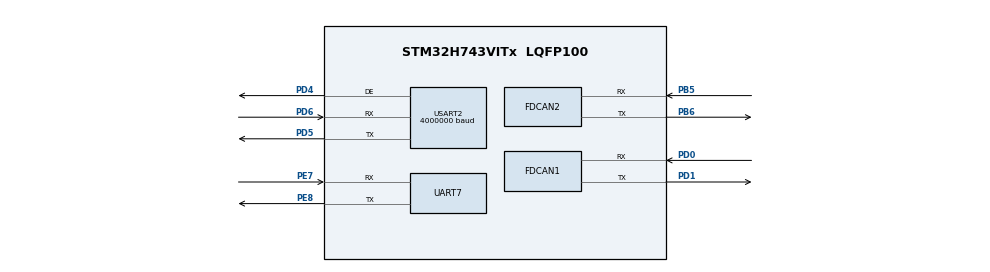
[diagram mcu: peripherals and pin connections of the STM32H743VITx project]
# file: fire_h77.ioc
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Dma.Request0=USART2_RX
Dma.Request1=USART2_TX
Dma.Request2=UART7_RX
Dma.UART7_RX.2.Direction=DMA_PERIPH_TO_MEMORY
Dma.UART7_RX.2.EventEnable=DISABLE
Dma.UART7_RX.2.FIFOMode=DMA_FIFOMODE_DISABLE
Dma.UART7_RX.2.Instance=DMA1_Stream2
Dma.UART7_RX.2.MemDataAlignment=DMA_MDATAALIGN_BYTE
Dma.UART7_RX.2.MemInc=DMA_MINC_ENABLE
Dma.UART7_RX.2.Mode=DMA_NORMAL
Dma.UART7_RX.2.PeriphDataAlignment=DMA_PDATAALIGN_BYTE
Dma.UART7_RX.2.PeriphInc=DMA_PINC_DISABLE
Dma.UART7_RX.2.Polarity=HAL_DMAMUX_REQ_GEN_RISING
Dma.UART7_RX.2.Priority=DMA_PRIORITY_LOW
Dma.UART7_RX.2.RequestNumber=1
Dma.UART7_RX.2.SignalID=NONE
Dma.UART7_RX.2.SyncEnable=DISABLE
Dma.UART7_RX.2.SyncPolarity=HAL_DMAMUX_SYNC_NO_EVENT
Dma.UART7_RX.2.SyncRequestNumber=1
Dma.UART7_RX.2.SyncSignalID=NONE
Dma.USART2_RX.0.Direction=DMA_PERIPH_TO_MEMORY
Dma.USART2_RX.0.EventEnable=DISABLE
Dma.USART2_RX.0.FIFOMode=DMA_FIFOMODE_DISABLE
Dma.USART2_RX.0.Instance=DMA1_Stream0
Dma.USART2_RX.0.MemDataAlignment=DMA_MDATAALIGN_BYTE
Dma.USART2_RX.0.MemInc=DMA_MINC_ENABLE
Dma.USART2_RX.0.Mode=DMA_NORMAL
Dma.USART2_RX.0.PeriphDataAlignment=DMA_PDATAALIGN_BYTE
Dma.USART2_RX.0.PeriphInc=DMA_PINC_DISABLE
Dma.USART2_RX.0.Polarity=HAL_DMAMUX_REQ_GEN_RISING
Dma.USART2_RX.0.Priority=DMA_PRIORITY_VERY_HIGH
Dma.USART2_RX.0.RequestNumber=1
Dma.USART2_RX.0.SignalID=NONE
Dma.USART2_RX.0.SyncEnable=DISABLE
Dma.USART2_RX.0.SyncPolarity=HAL_DMAMUX_SYNC_NO_EVENT
Dma.USART2_RX.0.SyncRequestNumber=1
Dma.USART2_RX.0.SyncSignalID=NONE
Dma.USART2_TX.1.Direction=DMA_MEMORY_TO_PERIPH
Dma.USART2_TX.1.EventEnable=DISABLE
Dma.USART2_TX.1.FIFOMode=DMA_FIFOMODE_DISABLE
Dma.USART2_TX.1.Instance=DMA1_Stream1
Dma.USART2_TX.1.MemDataAlignment=DMA_MDATAALIGN_BYTE
Dma.USART2_TX.1.MemInc=DMA_MINC_ENABLE
Dma.USART2_TX.1.Mode=DMA_NORMAL
Dma.USART2_TX.1.PeriphDataAlignment=DMA_PDATAALIGN_BYTE
Dma.USART2_TX.1.PeriphInc=DMA_PINC_DISABLE
Dma.USART2_TX.1.Polarity=HAL_DMAMUX_REQ_GEN_RISING
Dma.USART2_TX.1.Priority=DMA_PRIORITY_VERY_HIGH
Dma.USART2_TX.1.RequestNumber=1
Dma.USART2_TX.1.SignalID=NONE
Dma.USART2_TX.1.SyncEnable=DISABLE
Dma.USART2_TX.1.SyncPolarity=HAL_DMAMUX_SYNC_NO_EVENT
Dma.USART2_TX.1.SyncRequestNumber=1
Dma.USART2_TX.1.SyncSignalID=NONE
FDCAN1.CalculateBaudRateNominal=1000000
FDCAN1.CalculateTimeBitNominal=1000
FDCAN1.CalculateTimeQuantumNominal=50.0
FDCAN1.NominalPrescaler=6
FDCAN1.NominalTimeSeg1=13
FDCAN1.NominalTimeSeg2=6
FDCAN1.RxFifo0ElmtsNbr=64
FDCAN1.TxFifoQueueElmtsNbr=32
FDCAN2.CalculateBaudRateNominal=1000000
FDCAN2.CalculateTimeBitNominal=1000
FDCAN2.CalculateTimeQuantumNominal=50.0
FDCAN2.NominalPrescaler=6
FDCAN2.NominalTimeSeg1=13
FDCAN2.NominalTimeSeg2=6
FDCAN2.RxFifo1ElmtsNbr=64
FDCAN2.TxFifoQueueElmtsNbr=32
FREERTOS.Tasks01=defaultTask,24,128,StartDefaultTask,Default,NULL,Dynamic,NULL,NULL
Mcu.Family=STM32H7
Mcu.Name=STM32H743VITx
Mcu.Package=LQFP100
NVIC.DMA1_Stream0_IRQn=true\:5\:0\:false\:false\:true\:true\:false\:true\:true
NVIC.DMA1_Stream1_IRQn=true\:5\:0\:false\:false\:true\:true\:false\:true\:true
NVIC.DMA1_Stream2_IRQn=true\:5\:0\:false\:false\:true\:true\:false\:true\:true
NVIC.FDCAN1_IT0_IRQn=true\:5\:0\:false\:false\:true\:true\:true\:true\:true
NVIC.FDCAN2_IT1_IRQn=true\:5\:0\:false\:false\:true\:true\:true\:true\:true
NVIC.FDCAN_CAL_IRQn=true\:5\:0\:false\:false\:true\:true\:true\:true\:true
NVIC.PriorityGroup=NVIC_PRIORITYGROUP_4
NVIC.TIM1_UP_IRQn=true\:15\:0\:false\:false\:true\:false\:false\:true\:true
NVIC.TimeBase=TIM1_UP_IRQn
NVIC.TimeBaseIP=TIM1
NVIC.UART7_IRQn=true\:5\:0\:false\:false\:true\:true\:true\:true\:true
NVIC.USART2_IRQn=true\:5\:0\:false\:false\:true\:true\:true\:true\:true
PA13\ (JTMS/SWDIO).Mode=Serial_Wire
PA13\ (JTMS/SWDIO).Signal=DEBUG_JTMS-SWDIO
PA14\ (JTCK/SWCLK).Mode=Serial_Wire
PA14\ (JTCK/SWCLK).Signal=DEBUG_JTCK-SWCLK
PB5.Mode=FDCAN_Activate
PB5.Signal=FDCAN2_RX
PB6.Mode=FDCAN_Activate
PB6.Signal=FDCAN2_TX
PD0.Mode=FDCAN_Activate
PD0.Signal=FDCAN1_RX
PD1.Mode=FDCAN_Activate
PD1.Signal=FDCAN1_TX
PD4.GPIO_Speed=GPIO_SPEED_FREQ_VERY_HIGH
PD4.Mode=Hardware Flow Control (RS485)
PD4.Signal=USART2_DE
PD5.GPIO_Speed=GPIO_SPEED_FREQ_VERY_HIGH
PD5.Mode=Asynchronous
PD5.Signal=USART2_TX
PD6.GPIO_Speed=GPIO_SPEED_FREQ_VERY_HIGH
PD6.Mode=Asynchronous
PD6.Signal=USART2_RX
PE7.Mode=Asynchronous
PE7.Signal=UART7_RX
PE8.Mode=Asynchronous
PE8.Signal=UART7_TX
PH0-OSC_IN\ (PH0).Mode=HSE-External-Oscillator
PH0-OSC_IN\ (PH0).Signal=RCC_OSC_IN
PH1-OSC_OUT\ (PH1).Mode=HSE-External-Oscillator
PH1-OSC_OUT\ (PH1).Signal=RCC_OSC_OUT
ProjectManager.HeapSize=0x200
ProjectManager.StackSize=0x400
ProjectManager.TargetToolchain=MDK-ARM V5.32
RCC.ADCFreq_Value=129000000
RCC.APB1Freq_Value=120000000
RCC.APB2Freq_Value=120000000
RCC.APB3Freq_Value=120000000
RCC.APB4Freq_Value=120000000
RCC.CortexFreq_Value=480000000
RCC.D1PPRE=RCC_APB3_DIV2
RCC.D2PPRE1=RCC_APB1_DIV2
RCC.D2PPRE2=RCC_APB2_DIV2
RCC.D3PPRE=RCC_APB4_DIV2
RCC.DIVM1=4
RCC.DIVN1=60
RCC.DIVQ1=8
RCC.HCLKFreq_Value=240000000
RCC.HPRE=RCC_HCLK_DIV2
RCC.PLL2FRACN=0
RCC.PLL3FRACN=0
RCC.PLLFRACN=0
RCC.SYSCLKFreq_VALUE=480000000
RCC.SYSCLKSource=RCC_SYSCLKSOURCE_PLLCLK
RCC.USBFreq_Value=120000000
USART2.BaudRate=4000000
USART2.VirtualMode-Asynchronous=VM_ASYNC
USART2.VirtualMode-Hardware\ Flow\ Control\ (RS485)=VM_ASYNC
VP_FREERTOS_VS_CMSIS_V2.Mode=CMSIS_V2
VP_MEMORYMAP_VS_MEMORYMAP.Mode=CurAppReg
VP_SYS_VS_tim1.Mode=TIM1
board=custom

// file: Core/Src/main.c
/* USER CODE BEGIN Header */
/**
  ******************************************************************************
  * @file           : main.c
  * @brief          : Main program body
  ******************************************************************************
  * @attention
  *
  * Copyright (c) 2026 STMicroelectronics.
  * All rights reserved.
  *
  * This software is licensed under terms that can be found in the LICENSE file
  * in the root directory of this software component.
  * If no LICENSE file comes with this software, it is provided AS-IS.
  *
  ******************************************************************************
  */
/* USER CODE END Header */
#include "main.h"
#include "cmsis_os.h"
#include "dma.h"
#include "fdcan.h"
#include "usart.h"
#include "gpio.h"

void SystemClock_Config(void);
void MX_FREERTOS_Init(void);

int main(void)
{

  /* MCU Configuration--------------------------------------------------------*/

  /* Reset of all peripherals, Initializes the Flash interface and the Systick. */
  HAL_Init();

  /* Configure the system clock */
  SystemClock_Config();

  /* Initialize all configured peripherals */
  MX_GPIO_Init();
  MX_DMA_Init();
  MX_FDCAN1_Init();
  MX_USART2_UART_Init();
  MX_FDCAN2_Init();
  MX_UART7_Init();

  /* Init scheduler */
  osKernelInitialize();  /* Call init function for freertos objects (in cmsis_os2.c) */
  MX_FREERTOS_Init();

  /* Start scheduler */
  osKernelStart();

  /* We should never get here as control is now taken by the scheduler */

  /* Infinite loop */
  while (1)
  {

  }
}

void SystemClock_Config(void)
{
  RCC_OscInitTypeDef RCC_OscInitStruct = {0};
  RCC_ClkInitTypeDef RCC_ClkInitStruct = {0};

  /** Supply configuration update enable
  */
  HAL_PWREx_ConfigSupply(PWR_LDO_SUPPLY);

  /** Configure the main internal regulator output voltage
  */
  __HAL_PWR_VOLTAGESCALING_CONFIG(PWR_REGULATOR_VOLTAGE_SCALE0);

  while(!__HAL_PWR_GET_FLAG(PWR_FLAG_VOSRDY)) {}

  /** Initializes the RCC Oscillators according to the specified parameters
  * in the RCC_OscInitTypeDef structure.
  */
  RCC_OscInitStruct.OscillatorType = RCC_OSCILLATORTYPE_HSI;
  RCC_OscInitStruct.HSIState = RCC_HSI_DIV1;
  RCC_OscInitStruct.HSICalibrationValue = RCC_HSICALIBRATION_DEFAULT;
  RCC_OscInitStruct.PLL.PLLState = RCC_PLL_ON;
  RCC_OscInitStruct.PLL.PLLSource = RCC_PLLSOURCE_HSI;
  RCC_OscInitStruct.PLL.PLLM = 4;
  RCC_OscInitStruct.PLL.PLLN = 60;
  RCC_OscInitStruct.PLL.PLLP = 2;
  RCC_OscInitStruct.PLL.PLLQ = 8;
  RCC_OscInitStruct.PLL.PLLR = 2;
  RCC_OscInitStruct.PLL.PLLRGE = RCC_PLL1VCIRANGE_3;
  RCC_OscInitStruct.PLL.PLLVCOSEL = RCC_PLL1VCOWIDE;
  RCC_OscInitStruct.PLL.PLLFRACN = 0;
  if (HAL_RCC_OscConfig(&RCC_OscInitStruct) != HAL_OK)
  {
    Error_Handler();
  }

  /** Initializes the CPU, AHB and APB buses clocks
  */
  RCC_ClkInitStruct.ClockType = RCC_CLOCKTYPE_HCLK|RCC_CLOCKTYPE_SYSCLK
                              |RCC_CLOCKTYPE_PCLK1|RCC_CLOCKTYPE_PCLK2
                              |RCC_CLOCKTYPE_D3PCLK1|RCC_CLOCKTYPE_D1PCLK1;
  RCC_ClkInitStruct.SYSCLKSource = RCC_SYSCLKSOURCE_PLLCLK;
  RCC_ClkInitStruct.SYSCLKDivider = RCC_SYSCLK_DIV1;
  RCC_ClkInitStruct.AHBCLKDivider = RCC_HCLK_DIV2;
  RCC_ClkInitStruct.APB3CLKDivider = RCC_APB3_DIV2;
  RCC_ClkInitStruct.APB1CLKDivider = RCC_APB1_DIV2;
  RCC_ClkInitStruct.APB2CLKDivider = RCC_APB2_DIV2;
  RCC_ClkInitStruct.APB4CLKDivider = RCC_APB4_DIV2;

  if (HAL_RCC_ClockConfig(&RCC_ClkInitStruct, FLASH_LATENCY_4) != HAL_OK)
  {
    Error_Handler();
  }
}

void HAL_TIM_PeriodElapsedCallback(TIM_HandleTypeDef *htim)
{
  if (htim->Instance == TIM1)
  {
    HAL_IncTick();
  }
}

void Error_Handler(void)
{
  __disable_irq();
  while (1)
  {
  }
}

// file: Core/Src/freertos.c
/* USER CODE BEGIN Header */
/**
  ******************************************************************************
  * File Name          : freertos.c
  * Description        : Code for freertos applications
  ******************************************************************************
  * @attention
  *
  * Copyright (c) 2026 STMicroelectronics.
  * All rights reserved.
  *
  * This software is licensed under terms that can be found in the LICENSE file
  * in the root directory of this software component.
  * If no LICENSE file comes with this software, it is provided AS-IS.
  *
  ******************************************************************************
  */
/* USER CODE END Header */

#include "FreeRTOS.h"
#include "task.h"
#include "main.h"
#include "cmsis_os.h"

/* USER CODE BEGIN Includes */
#include "Task_Init.h"
/* USER CODE END Includes */

/* Definitions for defaultTask */
osThreadId_t defaultTaskHandle;
const osThreadAttr_t defaultTask_attributes = {
  .name = "defaultTask",
  .stack_size = 128 * 4,
  .priority = (osPriority_t) osPriorityNormal,
};

void StartDefaultTask(void *argument);

void MX_FREERTOS_Init(void); /* (MISRA C 2004 rule 8.1) */

void MX_FREERTOS_Init(void) {

  /* Create the thread(s) */
  /* creation of defaultTask */
  defaultTaskHandle = osThreadNew(StartDefaultTask, NULL, &defaultTask_attributes);

}

void StartDefaultTask(void *argument)
{
  /* USER CODE BEGIN StartDefaultTask */
  /* Infinite loop */
	Task_Init();
  for(;;)
  {

    osDelay(1);
  }
  /* USER CODE END StartDefaultTask */
}
